# AVR128DB64 device description
Architecture: AVR8X; Family: AVR
Registers are 8-bit, read-write, reset 0x0 unless marked. A register's access mark holds for its fields unless they carry their own. Offsets are from the block's base; [hi:lo] are bit positions; {n}, {i} and the like mark numbered series; 'fields as' and 'values as' point back to an identical list; <NAME> marks a mode.

## TWI — Two-Wire Interface
Instances: TWI0 0x0900, TWI1 0x0920
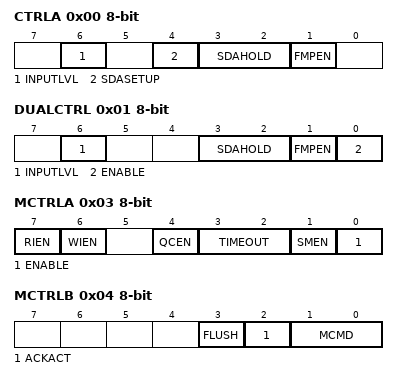
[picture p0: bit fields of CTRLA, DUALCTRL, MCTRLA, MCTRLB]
0x00 CTRLA — Control A
  [6] INPUTLVL <DEFAULT> — Input Voltage Transition Level
    0=I2C (I2C input voltage transition level); 1=SMBUS (SMBus 3.0 input voltage transition level)
  [4] SDASETUP <DEFAULT> — SDA Setup Time
    0=4CYC (SDA setup time is 4 clock cycles); 1=8CYC (SDA setup time is 8 clock cycles)
  [3:2] SDAHOLD <DEFAULT> — SDA Hold Time
    0=OFF (SDA hold time off); 1=50NS (Typical 50ns hold time); 2=300NS (Typical 300ns hold time); 3=500NS (Typical 500ns hold time)
  [1] FMPEN <DEFAULT> — FM Plus Enable
0x01 DUALCTRL — Dual Control
  [6] INPUTLVL <DEFAULT> — Input Voltage Transition Level
    values as CTRLA.INPUTLVL<DEFAULT>
  [3:2] SDAHOLD <DEFAULT> — SDA Hold Time
    values as CTRLA.SDAHOLD<DEFAULT>
  [1] FMPEN <DEFAULT> — FM Plus Enable
  [0] ENABLE <DEFAULT> — Dual Control Enable
0x02 DBGCTRL — Debug Control Register
  [0] DBGRUN <DEFAULT> — Debug Run
0x03 MCTRLA — Host Control A
  [7] RIEN — Read Interrupt Enable
  [6] WIEN — Write Interrupt Enable
  [4] QCEN — Quick Command Enable
  [3:2] TIMEOUT — Inactive Bus Timeout
    0=DISABLED (Bus Timeout Disabled); 1=50US (50 Microseconds); 2=100US (100 Microseconds); 3=200US (200 Microseconds)
  [1] SMEN — Smart Mode Enable
  [0] ENABLE — Enable TWI Host
0x04 MCTRLB — Host Control B
  [3] FLUSH
  [2] ACKACT — Acknowledge Action
    0=ACK (Send ACK); 1=NACK (Send NACK)
  [1:0] MCMD — Command
    0=NOACT (No Action); 1=REPSTART (Issue Repeated Start Condition); 2=RECVTRANS (Receive or Transmit Data, depending on DIR); 3=STOP (Issue Stop Condition)
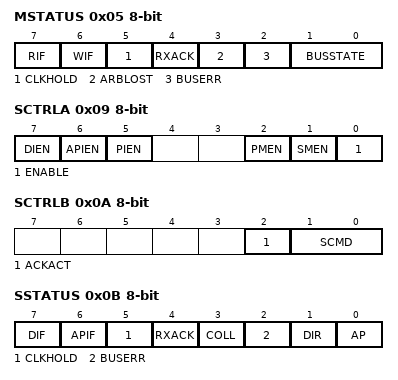
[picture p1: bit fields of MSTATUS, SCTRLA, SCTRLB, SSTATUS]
0x05 MSTATUS — Host Status
  [7] RIF — Read Interrupt Flag
  [6] WIF — Write Interrupt Flag
  [5] CLKHOLD — Clock Hold
  [4] RXACK ro — Received Acknowledge
  [3] ARBLOST — Arbitration Lost
  [2] BUSERR — Bus Error
  [1:0] BUSSTATE
    0=UNKNOWN (Unknown Bus State); 1=IDLE (Bus is Idle); 2=OWNER (This Module Controls The Bus); 3=BUSY (The Bus is Busy)
0x06 MBAUD reset not defined — Host Baud Rate Control
0x07 MADDR reset not defined — Host Address
0x08 MDATA reset not defined — Host Data
0x09 SCTRLA — Client Control A
  [7] DIEN — Data Interrupt Enable
  [6] APIEN — Address/Stop Interrupt Enable
  [5] PIEN — Stop Interrupt Enable
  [2] PMEN — Promiscuous Mode Enable
  [1] SMEN — Smart Mode Enable
  [0] ENABLE — Enable TWI Client
0x0A SCTRLB — Client Control B
  [2] ACKACT — Acknowledge Action
    0=ACK (Send ACK); 1=NACK (Send NACK)
  [1:0] SCMD — Command
    0=NOACT (No Action); 2=COMPTRANS (Used To Complete a Transaction); 3=RESPONSE (Used in Response to Address/Data Interrupt)
0x0B SSTATUS — Client Status
  [7] DIF — Data Interrupt Flag
  [6] APIF — Address/Stop Interrupt Flag
  [5] CLKHOLD ro — Clock Hold
  [4] RXACK ro — Received Acknowledge
  [3] COLL — Collision
  [2] BUSERR — Bus Error
  [1] DIR ro — Read/Write Direction
  [0] AP ro — Client Address or Stop
    0=STOP (Stop condition generated APIF); 1=ADR (Address detection generated APIF)
0x0C SADDR reset not defined — Client Address
0x0D SDATA reset not defined — Client Data
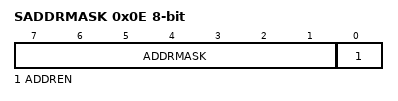
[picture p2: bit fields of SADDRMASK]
0x0E SADDRMASK reset not defined — Client Address Mask
  [7:1] ADDRMASK — Address Mask
  [0] ADDREN — Address Enable

## USART — Universal Synchronous and Asynchronous Receiver and Transmitter
Instances: USART{n} {0x800+0x20*n} (n=0..5)
0x00 RXDATAL ro — Receive Data Low Byte
  [7:0] DATA — RX Data
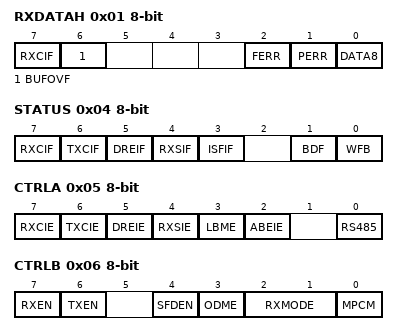
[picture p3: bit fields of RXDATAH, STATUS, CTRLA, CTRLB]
0x01 RXDATAH ro — Receive Data High Byte
  [7] RXCIF — Receive Complete Interrupt Flag
  [6] BUFOVF — Buffer Overflow
  [2] FERR — Frame Error
  [1] PERR — Parity Error
  [0] DATA8 — Receiver Data Register
0x02 TXDATAL — Transmit Data Low Byte
  [7:0] DATA — Transmit Data Register
0x03 TXDATAH — Transmit Data High Byte
  [0] DATA8 — Transmit Data Register (CHSIZE=9bit)
0x04 STATUS
  [7] RXCIF ro — Receive Complete Interrupt Flag
  [6] TXCIF — Transmit Interrupt Flag
  [5] DREIF ro — Data Register Empty Flag
  [4] RXSIF — Receive Start Interrupt
  [3] ISFIF — Inconsistent Sync Field Interrupt Flag
  [1] BDF — Break Detected Flag
  [0] WFB — Wait For Break
0x05 CTRLA — Control A
  [7] RXCIE — Receive Complete Interrupt Enable
  [6] TXCIE — Transmit Complete Interrupt Enable
  [5] DREIE — Data Register Empty Interrupt Enable
  [4] RXSIE — Receiver Start Frame Interrupt Enable
  [3] LBME — Loop-back Mode Enable
  [2] ABEIE — Auto-baud Error Interrupt Enable
  [0] RS485 — RS485 Mode internal transmitter
    0=DISABLE (RS485 Mode disabled); 1=ENABLE (RS485 Mode enabled)
0x06 CTRLB — Control B
  [7] RXEN — Reciever enable
  [6] TXEN — Transmitter Enable
  [4] SFDEN — Start Frame Detection Enable
  [3] ODME — Open Drain Mode Enable
  [2:1] RXMODE — Receiver Mode
    0=NORMAL (Normal mode); 1=CLK2X (CLK2x mode); 2=GENAUTO (Generic autobaud mode); 3=LINAUTO (LIN constrained autobaud mode)
  [0] MPCM — Multi-processor Communication Mode
0x07 CTRLC reset 0x3 — Control C
  [7:6] CMODE <MSPI> — Communication Mode
    0=ASYNCHRONOUS (Asynchronous Mode); 1=SYNCHRONOUS (Synchronous Mode); 2=IRCOM (Infrared Communication); 3=MSPI (SPI Host Mode)
  [2] UDORD <MSPI> — SPI Host Mode, Data Order
  [1] UCPHA <MSPI> — SPI Host Mode, Clock Phase
  [7:6] CMODE <NORMAL> — Communication Mode
    values as CMODE<MSPI>
  [5:4] PMODE <NORMAL> — Parity Mode
    0=DISABLED (No Parity); 2=EVEN (Even Parity); 3=ODD (Odd Parity)
  [3] SBMODE <NORMAL> — Stop Bit Mode
    0=1BIT (1 stop bit); 1=2BIT (2 stop bits)
  [2:0] CHSIZE <NORMAL> — Character Size
    {v}={v+5}BIT (Character size: {v+5} bit) (v=0..3); 6=9BITL (Character size: 9 bit read low byte first); 7=9BITH (Character size: 9 bit read high byte first)
0x08 BAUD 16-bit — Baud Rate
0x0A CTRLD — Control D
  [7:6] ABW — Auto Baud Window
    0=WDW0 (18% tolerance); 1=WDW1 (15% tolerance); 2=WDW2 (21% tolerance); 3=WDW3 (25% tolerance)
0x0B DBGCTRL — Debug Control
  [0] DBGRUN — Debug Run
0x0C EVCTRL — Event Control
  [0] IREI — IrDA Event Input Enable
0x0D TXPLCTRL — IRCOM Transmitter Pulse Length Control
  [7:0] TXPL — Transmit pulse length
0x0E RXPLCTRL — IRCOM Receiver Pulse Length Control
  [6:0] RXPL — Receiver Pulse Lenght

## USERROW
Instances: USERROW 0x1080
{0x0+i} USERROW{i} reset not defined (i=0..31) — User Row Byte {i}

## VPORT — Virtual Ports
Instances: VPORTA 0x0000, VPORTB 0x0004, VPORTC 0x0008, VPORTD 0x000C, VPORTE 0x0010, VPORTF 0x0014, VPORTG 0x0018
0x00 DIR reset not defined — Data Direction
0x01 OUT reset not defined — Output Value
0x02 IN reset not defined — Input Value
0x03 INTFLAGS — Interrupt Flags
  [7:0] INT — Pin Interrupt

## VREF — Voltage reference
Instances: VREF 0x00B0
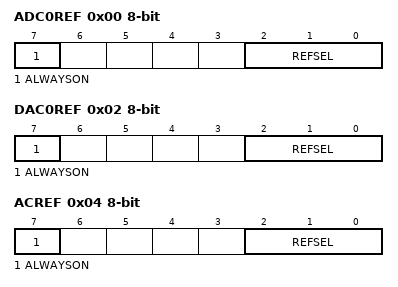
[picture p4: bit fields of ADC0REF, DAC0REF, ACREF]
0x00 ADC0REF — ADC0 Reference
  [7] ALWAYSON
  [2:0] REFSEL — Reference select
    0=1V024 (Internal 1.024V reference); 1=2V048 (Internal 2.048V reference); 2=4V096 (Internal 4.096V reference); 3=2V500 (Internal 2.500V reference); 5=VDD (VDD as reference); 6=VREFA (External reference on VREFA pin)
0x02 DAC0REF — DAC0 Reference
  fields as ADC0REF
0x04 ACREF — AC Reference
  fields as ADC0REF

## WDT — Watch-Dog Timer
Instances: WDT 0x0100
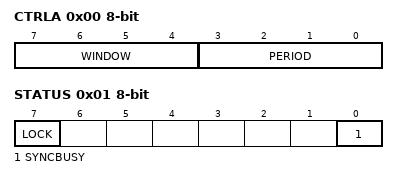
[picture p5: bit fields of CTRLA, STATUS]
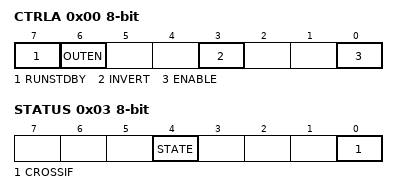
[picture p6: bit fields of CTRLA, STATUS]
0x00 CTRLA — Control A
  [7:4] WINDOW
    0=OFF; 1=8CLK (8 cycles (8ms)); 2=16CLK (16 cycles (16ms)); 3=32CLK (32 cycles (32ms)); 4=64CLK (64 cycles (64ms)); 5=128CLK (128 cycles (0.128s)); 6=256CLK (256 cycles (0.256s)); 7=512CLK (512 cycles (0.512s)); 8=1KCLK (1K cycles (1.0s)); 9=2KCLK (2K cycles (2.0s)); 10=4KCLK (4K cycles (4.1s)); 11=8KCLK (8K cycles (8.2s))
  [3:0] PERIOD
    values as WINDOW
0x01 STATUS
  [7] LOCK — Lock enable
  [0] SYNCBUSY ro — Syncronization busy

## ZCD — Zero Cross Detect
Instances: ZCD0 0x06C0, ZCD1 0x06C8, ZCD2 0x06D0
0x00 CTRLA — Control A
  [7] RUNSTDBY — Run in Standby Mode
  [6] OUTEN — Output Pad Enable
  [3] INVERT — Invert signal from pin
  [0] ENABLE
0x02 INTCTRL — Interrupt Control
  [1:0] INTMODE — Interrupt Mode
    0=NONE (No interrupt); 1=RISING (Interrupt on rising input signal); 2=FALLING (Interrupt on falling input signal); 3=BOTH (Interrupt on both rising and falling input signal)
0x03 STATUS
  [4] STATE ro — ZCD State
    0=LOW (Output is 0); 1=HIGH (Output is 1)
  [0] CROSSIF — ZCD Interrupt Flag
